# trimsir_me15 register map
Registers are access not given, no defined reset value unless marked. A register's access mark holds for its fields unless they carry their own. Offsets are from the block's base; lines under a group give offsets from that group; [hi:lo] are bit positions; {n}, {i} and the like mark numbered series; 'fields as' and 'values as' point back to an identical list; <NAME> marks a mode.

## Memory map
0x40105400 ECC size 0x400 — Error Correction Code

## ECC — Error Correction Code
Base 0x40105400
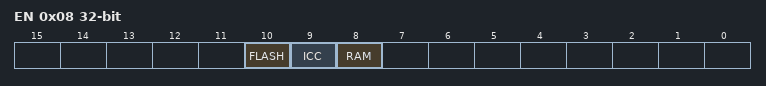
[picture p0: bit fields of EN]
0x08 EN — ECC Enable Register
  [all] fields
    0=dis (disabled); 1=en (enabled)
  [10] FLASH — Flash ECC Enable.
  [9] ICC — Instruction Cache 0 ECC Enable.
  [8] RAM — System RAM ECC Enable.
